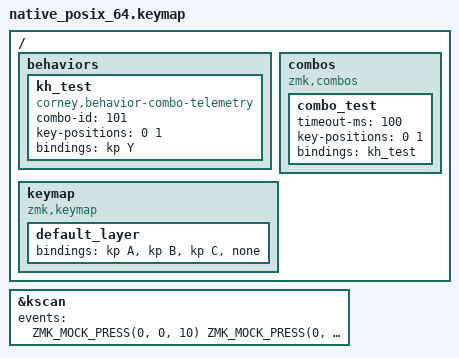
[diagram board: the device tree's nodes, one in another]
#include <behaviors.dtsi>
#include <dt-bindings/zmk/keys.h>
#include <dt-bindings/zmk/kscan_mock.h>

/ {
    behaviors {
        kh_test: kh_test {
            compatible = "corney,behavior-combo-telemetry";
            #binding-cells = <0>;
            combo-id = <101>;
            key-positions = <0 1>;
            bindings = <&kp Y>;
        };
    };

    combos {
        compatible = "zmk,combos";

        combo_test {
            timeout-ms = <100>;
            key-positions = <0 1>;
            bindings = <&kh_test>;
        };
    };

    keymap {
        compatible = "zmk,keymap";

        default_layer {
            bindings = <&kp A &kp B &kp C &none>;
        };
    };
};

&kscan {
    events = <
        ZMK_MOCK_PRESS(0, 0, 10)
        ZMK_MOCK_PRESS(0, 1, 10)
        ZMK_MOCK_RELEASE(0, 0, 10)
        ZMK_MOCK_RELEASE(0, 1, 10)
    >;
};
